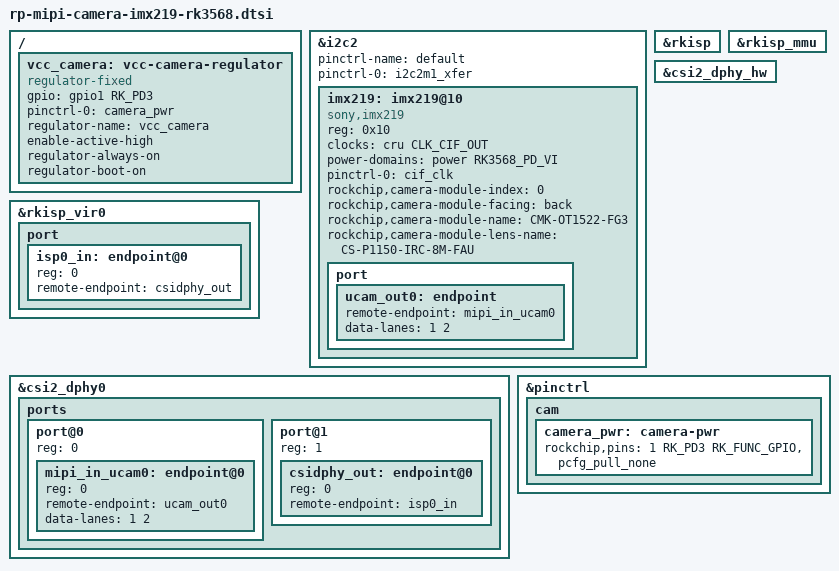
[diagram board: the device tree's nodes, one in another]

/ {
        vcc_camera: vcc-camera-regulator {
                compatible = "regulator-fixed";
                gpio = <&gpio1 RK_PD3 GPIO_ACTIVE_HIGH>;
                pinctrl-names = "default";
                pinctrl-0 = <&camera_pwr>;
                regulator-name = "vcc_camera";
                enable-active-high;
                regulator-always-on;
                regulator-boot-on;
        };
};

&i2c2 {
        status = "okay";
		pinctrl-name = "default";
		pinctrl-0 = <&i2c2m1_xfer>;

	imx219: imx219@10 {
                compatible = "sony,imx219";
                status = "okay";
                //reg = <0x1a>;
				reg = <0x10>;
                clocks = <&cru CLK_CIF_OUT>;
                clock-names = "xvclk";
                // conflict with csi-ctl-gpios//
              //  pwdn-gpios = <&gpio3 RK_PD5 GPIO_ACTIVE_HIGH>;
              //  reset-gpios = <&gpio1 RK_PD0 GPIO_ACTIVE_HIGH>;
				power-domains = <&power RK3568_PD_VI>;
                pinctrl-names = "default";
                pinctrl-0 = <&cif_clk>;
                rockchip,camera-module-index = <0>;
                rockchip,camera-module-facing = "back";
                rockchip,camera-module-name = "CMK-OT1522-FG3";
                rockchip,camera-module-lens-name = "CS-P1150-IRC-8M-FAU";
				
                port {
                        ucam_out0: endpoint {
                                remote-endpoint = <&mipi_in_ucam0>;
                                data-lanes = <1 2>;
                        };
                };
        };

	
	
};


&rkisp {
        status = "okay";
};

&rkisp_mmu {
        status = "okay";
};

&rkisp_vir0 {
        status = "okay";

        port {
                #address-cells = <1>;
                #size-cells = <0>;

                isp0_in: endpoint@0 {
                        reg = <0>;
                        remote-endpoint = <&csidphy_out>;
                };
        };
};

&csi2_dphy_hw {
        status = "okay";
};



&csi2_dphy0 {
        status = "okay";

        ports {
                #address-cells = <1>;
                #size-cells = <0>;
                port@0 {
                        reg = <0>;
                        #address-cells = <1>;
                        #size-cells = <0>;

                        mipi_in_ucam0: endpoint@0 {
                                reg = <0>;
                                remote-endpoint = <&ucam_out0>;
                                data-lanes = <1 2>;
                        };
/*
                        mipi_in_ucam1: endpoint@1 {
                                reg = <1>;
                                remote-endpoint = <&ucam_out1>;
                                data-lanes = <1 2 3 4>;
                        };

                        mipi_in_ucam2: endpoint@2 {
                                reg = <2>;
                                remote-endpoint = <&ucam_out2>;
                                data-lanes = <1 2 3 4>;
                        };
						*/
              };
                port@1 {
                        reg = <1>;
                        #address-cells = <1>;
                        #size-cells = <0>;

                        csidphy_out: endpoint@0 {
                                reg = <0>;
                                remote-endpoint = <&isp0_in>;
                        };
                };
        };
};


&pinctrl {
        cam {
                camera_pwr: camera-pwr {
                        rockchip,pins =
                                /* camera power en */
                                <1 RK_PD3 RK_FUNC_GPIO &pcfg_pull_none>;
                };
        };
};
